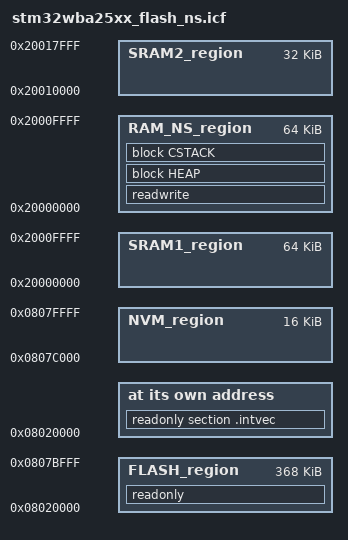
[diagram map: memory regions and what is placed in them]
/**********************************************************************************/
/**** Linker File (ICF)                                                        ****/
/**********************************************************************************/

/*-Series memory map-*/
define symbol __FLASH_BASE__              = 0x08000000;
define symbol __FLASH_TOP__               = 0x0807FFFF;
define symbol __SRAM1_BASE__              = 0x20000000;
define symbol __SRAM1_TOP__               = 0x2000FFFF;
define symbol __SRAM2_BASE__              = 0x20010000;
define symbol __SRAM2_TOP__               = 0x20017FFF;

/*-Flash layout-*/
define symbol __region_NVM_size__         = 0x4000;
define symbol __region_NVM_end__          = __FLASH_TOP__;
define symbol __region_NVM_start__        = __region_NVM_end__ - __region_NVM_size__ + 0x1;
define symbol __region_FLASH_start__      = 0x08020000;
define symbol __region_FLASH_end__        = __region_NVM_start__ - 0x1;

/*-RAM layout-*/
define symbol __region_SRAM1_start__      = __SRAM1_BASE__;
define symbol __region_SRAM1_end__        = __SRAM1_TOP__;
define symbol __region_SRAM2_start__      = __SRAM2_BASE__;
define symbol __region_SRAM2_end__        = __SRAM2_TOP__;
define symbol __region_RAM_NS_start__     = __SRAM1_BASE__;
define symbol __region_RAM_NS_end__       = __SRAM1_TOP__;

/*-Stack and heap-*/
define symbol __ICFEDIT_size_heap__   = 0x0000;
define symbol __ICFEDIT_size_cstack__ = 0x1000;
define symbol __intvec_start__            = __region_FLASH_start__;

/*-Regions-*/
define memory mem with size = 4G;
define region NVM_region        = mem:[from __region_NVM_start__ to __region_NVM_end__];
define region FLASH_region      = mem:[from __region_FLASH_start__ to __region_FLASH_end__];
define region SRAM1_region      = mem:[from __region_SRAM1_start__ to __region_SRAM1_end__];
define region SRAM2_region      = mem:[from __region_SRAM2_start__ to __region_SRAM2_end__];
define region SRAM_region       = SRAM1_region | SRAM2_region;
define region RAM_NS_region     = mem:[from __region_RAM_NS_start__ to __region_RAM_NS_end__];

/*-Blocks-*/
define block HEAP   with alignment = 8, size = __ICFEDIT_size_heap__   { };
define block CSTACK with alignment = 8, size = __ICFEDIT_size_cstack__ { };

/*-Initialization strategies-*/
initialize by copy { readwrite };
do not initialize  { section .noinit };

/*-Sections placements-*/
place at address mem:__intvec_start__ { readonly section .intvec };
place in NVM_region         { };
place in FLASH_region       { readonly };
place in SRAM1_region       { };
place in SRAM2_region       { };
place in SRAM_region        { };
place in RAM_NS_region      { readwrite, block HEAP, block CSTACK };
